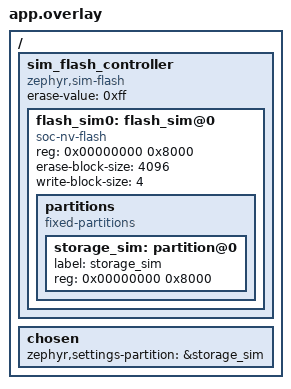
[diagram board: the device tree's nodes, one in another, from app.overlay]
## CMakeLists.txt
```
cmake_minimum_required(VERSION 3.20.0)
find_package(Zephyr REQUIRED HINTS $ENV{ZEPHYR_BASE})
project(riepilogo_modulo7)

target_sources(app PRIVATE src/main.c)
```

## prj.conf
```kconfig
# Esercizio modulo7/08_riepilogo

# LED
CONFIG_GPIO=y
# Shell e logging
CONFIG_SHELL=y
CONFIG_LOG=y
# Flash simulata + NVS + settings (vedi app.overlay)
CONFIG_FLASH=y
CONFIG_FLASH_MAP=y
CONFIG_FLASH_PAGE_LAYOUT=y
CONFIG_FLASH_SIMULATOR=y
CONFIG_NVS=y
CONFIG_SETTINGS=y
CONFIG_SETTINGS_NVS=y
```

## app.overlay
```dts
/*
 * Flash simulata per Renode: identica a modulo7/07_settings/app.overlay
 * (leggi la spiegazione li'). Gia' pronta, non fa parte dell'esercizio.
 */

/ {
	sim_flash_controller: sim_flash_controller {
		compatible = "zephyr,sim-flash";
		#address-cells = <1>;
		#size-cells = <1>;
		erase-value = <0xff>;

		flash_sim0: flash_sim@0 {
			compatible = "soc-nv-flash";
			reg = <0x00000000 0x8000>;
			erase-block-size = <4096>;
			write-block-size = <4>;

			partitions {
				compatible = "fixed-partitions";
				#address-cells = <1>;
				#size-cells = <1>;

				storage_sim: partition@0 {
					label = "storage_sim";
					reg = <0x00000000 0x8000>;
				};
			};
		};
	};

	chosen {
		zephyr,settings-partition = &storage_sim;
	};
};
```

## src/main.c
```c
/*
 * Esercizio 8 (Modulo 7) - Riepilogo: lampeggio configurabile e salvato
 *
 * Teoria: teoria/08_strumenti_debug_test.md, sezioni 1, 2 e 7.
 *
 * OBIETTIVO
 * Un firmware completo in piccolo: led0 lampeggia; dalla shell si cambia il periodo e
 * si accende/spegne il lampeggio; la configurazione viene salvata con settings e
 * ricaricata all'avvio; i messaggi passano dal logging.
 *
 *     blink stato            -> "periodo: 500 ms, attivo: si"
 *     blink periodo <ms>     -> "periodo = 200 ms (salvato)"   (ammessi 50..5000)
 *     blink on               -> "lampeggio attivo"             (salvato)
 *     blink off              -> "lampeggio fermo"              (salvato, LED spento)
 *
 * PASSI
 * 1. Configurazione in una struct globale:
 *        struct config { uint32_t periodo_ms; bool attivo; };
 *    con valori predefiniti 500 ms e attivo. Proteggila con un k_mutex: la scrivono i
 *    comandi della shell (thread della shell) e la legge il thread del lampeggio.
 * 2. Settings con prefisso "blink": chiavi "blink/periodo" e "blink/attivo"; handler set
 *    come nell'esercizio 7. All'avvio: settings_subsys_init + settings_load, poi
 *    LOG_INF("Config caricata: periodo %u ms, attivo %d", ...).
 * 3. Thread "lampeggio" (K_THREAD_DEFINE, stack 1024, priorita' 7): se attivo inverte
 *    led0, se no lo tiene spento; poi dorme periodo_ms / 2 (un periodo = acceso+spento).
 *    Leggi la config sotto mutex e copiala in variabili locali PRIMA di dormire.
 * 4. Comandi della shell "blink" con sottocomandi stato, periodo, on, off. Per
 *    "periodo" usa strtol e controlla l'intervallo 50..5000; se non va bene:
 *        shell_error(sh, "valore non valido: %s (ammessi 50..5000)", argv[1]);
 *    Dopo ogni modifica salva con settings_save_one e conferma.
 * 5. Prova a mano con esegui.ps1: cambia periodo, guarda il LED nel monitor
 *    (sysbus.gpioPortD.led0 State piu' volte).
 *
 * OUTPUT ATTESO
 *     [..] <inf> app: Config caricata: periodo 500 ms, attivo 1
 *     uart:~$ blink periodo 200
 *     periodo = 200 ms (salvato)
 *     uart:~$ blink stato
 *     periodo: 200 ms, attivo: si
 *     uart:~$ blink off
 *     lampeggio fermo
 *     uart:~$ blink periodo 10
 *     valore non valido: 10 (ammessi 50..5000)
 *
 * CONCETTI NUOVI
 * - Mettere insieme: shell + thread + mutex + settings + GPIO + log.
 * - Dati condivisi tra il thread della shell e un thread tuo: mutex obbligatorio.
 * - Validare SEMPRE l'input dell'utente prima di usarlo e salvarlo.
 *
 * COME VERIFICARE DA SOLO
 *     .\verifica.ps1 modulo7\08_riepilogo
 *
 * ERRORI TIPICI
 * - Dormire tenendo il mutex: la shell resta bloccata finche' il thread non si sveglia.
 * - Spegnere il lampeggio senza spegnere il LED: resta acceso se era acceso in quel momento.
 * - Salvare bool con sizeof(int): len non torna al caricamento.
 * - Cambiare periodo e accorgersene solo dopo il vecchio periodo (accettabile: perche'?
 *   Vedi bonus).
 *
 * BONUS (facoltativo)
 * - Il nuovo periodo deve valere SUBITO, anche se il thread sta dormendo 5 s: usa un
 *   k_sem (o k_event) per svegliarlo dal comando, e k_sem_take con timeout al posto
 *   dello sleep.
 * - Comando "blink reset": torna ai valori predefiniti (settings_delete).
 * - Aggiungi un test ztest per la funzione che valida il periodo (spostala in un file
 *   separato senza dipendenze dalla shell).
 *
 * Scrivi il tuo codice qui sotto.
 */

#include <stdlib.h>
#include <errno.h>
#include <string.h>
#include <zephyr/kernel.h>
#include <zephyr/drivers/gpio.h>
#include <zephyr/shell/shell.h>
#include <zephyr/settings/settings.h>
#include <zephyr/logging/log.h>

LOG_MODULE_REGISTER(app, LOG_LEVEL_INF);

/* TODO: config, mutex, led0, settings, thread lampeggio, comandi blink. */

int main(void)
{
	/* TODO: prepara led0, settings_subsys_init, settings_load. */
	return 0;
}
```
